AUTOSAR XML (schema 4-2-2)
package /STELLANTIS/EPT/ASWCs
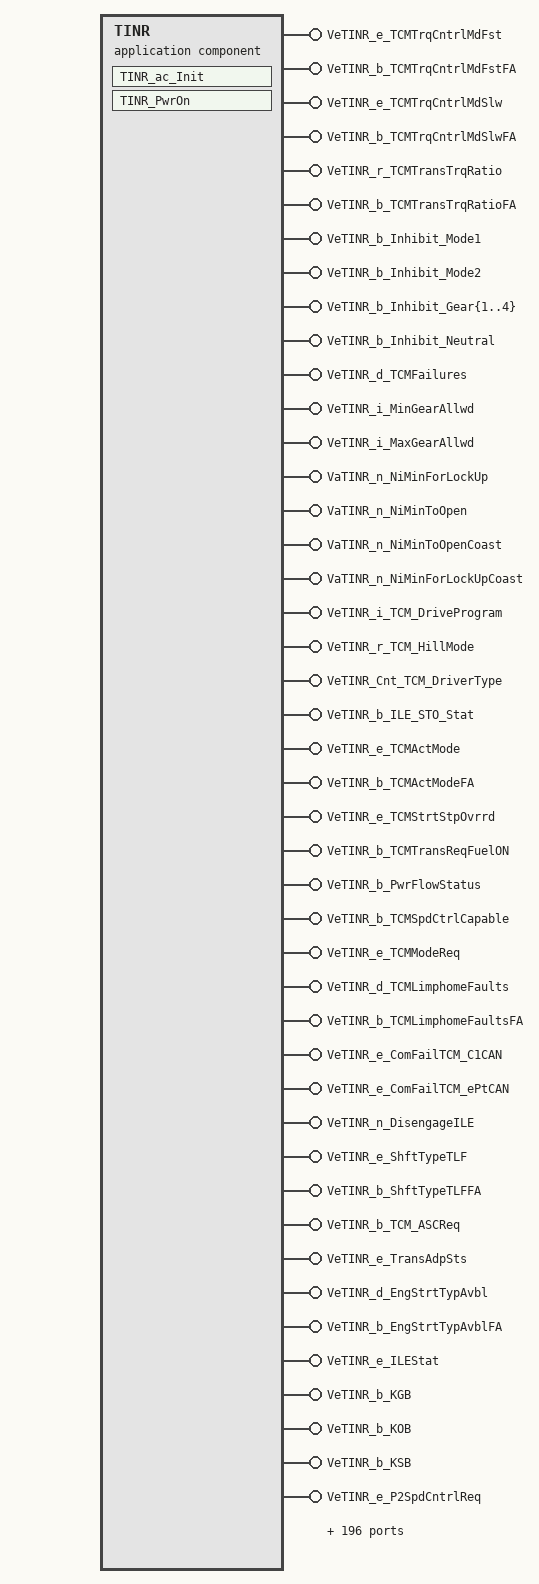
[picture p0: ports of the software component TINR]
  application sw component type TINR
    249 x provide port:
      VeTINR_e_TCMTrqCntrlMdFst: nonqueued-sender-com-spec{data-element=Value, init-value=CeTINR_e_None}, provided-interface=VeTINR_e_TCMTrqCntrlMdFst
      VeTINR_b_TCMTrqCntrlMdFstFA: nonqueued-sender-com-spec{data-element=Value, init-value=0}, provided-interface=VeTINR_b_TCMTrqCntrlMdFstFA
      VeTINR_e_TCMTrqCntrlMdSlw: nonqueued-sender-com-spec{data-element=Value, init-value=CeTINR_e_None}, provided-interface=VeTINR_e_TCMTrqCntrlMdSlw
      VeTINR_b_TCMTrqCntrlMdSlwFA: nonqueued-sender-com-spec{data-element=Value, init-value=0}, provided-interface=VeTINR_b_TCMTrqCntrlMdSlwFA
      VeTINR_r_TCMTransTrqRatio: nonqueued-sender-com-spec{data-element=Value, init-value=0}, provided-interface=VeTINR_r_TCMTransTrqRatio
      VeTINR_b_TCMTransTrqRatioFA: nonqueued-sender-com-spec{data-element=Value, init-value=0}, provided-interface=VeTINR_b_TCMTransTrqRatioFA
      VeTINR_b_Inhibit_Mode1: nonqueued-sender-com-spec{data-element=Value, init-value=0}, provided-interface=VeTINR_b_Inhibit_Mode1
      VeTINR_b_Inhibit_Mode2: nonqueued-sender-com-spec{data-element=Value, init-value=0}, provided-interface=VeTINR_b_Inhibit_Mode2
      VeTINR_b_Inhibit_Gear{1..4}: nonqueued-sender-com-spec{data-element=Value, init-value=0}, provided-interface=VeTINR_b_Inhibit_Gear{1..4}
      VeTINR_b_Inhibit_Neutral: nonqueued-sender-com-spec{data-element=Value, init-value=0}, provided-interface=VeTINR_b_Inhibit_Neutral
      VeTINR_d_TCMFailures: nonqueued-sender-com-spec{data-element=Value, init-value=0}, provided-interface=VeTINR_d_TCMFailures
      VeTINR_i_MinGearAllwd: nonqueued-sender-com-spec{data-element=Value, init-value=0}, provided-interface=VeTINR_i_MinGearAllwd
      VeTINR_i_MaxGearAllwd: nonqueued-sender-com-spec{data-element=Value, init-value=0}, provided-interface=VeTINR_i_MaxGearAllwd
      VaTINR_n_NiMinForLockUp: nonqueued-sender-com-spec{data-element=Value, init-value=9 x 0}, provided-interface=VaTINR_n_NiMinForLockUp
      VaTINR_n_NiMinToOpen: nonqueued-sender-com-spec{data-element=Value, init-value=9 x 0}, provided-interface=VaTINR_n_NiMinToOpen
      VaTINR_n_NiMinToOpenCoast: nonqueued-sender-com-spec{data-element=Value, init-value=9 x 0}, provided-interface=VaTINR_n_NiMinToOpenCoast
      VaTINR_n_NiMinForLockUpCoast: nonqueued-sender-com-spec{data-element=Value, init-value=9 x 0}, provided-interface=VaTINR_n_NiMinForLockUpCoast
      VeTINR_i_TCM_DriveProgram: nonqueued-sender-com-spec{data-element=Value, init-value=0}, provided-interface=VeTINR_i_TCM_DriveProgram
      VeTINR_r_TCM_HillMode: nonqueued-sender-com-spec{data-element=Value, init-value=0}, provided-interface=VeTINR_r_TCM_HillMode
      VeTINR_Cnt_TCM_DriverType: nonqueued-sender-com-spec{data-element=Value, init-value=0}, provided-interface=VeTINR_Cnt_TCM_DriverType
      VeTINR_b_ILE_STO_Stat: nonqueued-sender-com-spec{data-element=Value, init-value=0}, provided-interface=VeTINR_b_ILE_STO_Stat
      VeTINR_e_TCMActMode: nonqueued-sender-com-spec{data-element=Value, init-value=CeTRNR_e_SerEngOff}, provided-interface=VeTINR_e_TCMActMode
      VeTINR_b_TCMActModeFA: nonqueued-sender-com-spec{data-element=Value, init-value=0}, provided-interface=VeTINR_b_TCMActModeFA
      VeTINR_e_TCMStrtStpOvrrd: nonqueued-sender-com-spec{data-element=Value, init-value=CeSTRR_e_NoOvrrd}, provided-interface=VeTINR_e_TCMStrtStpOvrrd
      VeTINR_b_TCMTransReqFuelON: nonqueued-sender-com-spec{data-element=Value, init-value=0}, provided-interface=VeTINR_b_TCMTransReqFuelON
      VeTINR_b_PwrFlowStatus: nonqueued-sender-com-spec{data-element=Value, init-value=0}, provided-interface=VeTINR_b_PwrFlowStatus
      VeTINR_b_TCMSpdCtrlCapable: nonqueued-sender-com-spec{data-element=Value, init-value=0}, provided-interface=VeTINR_b_TCMSpdCtrlCapable
      VeTINR_e_TCMModeReq: nonqueued-sender-com-spec{data-element=Value, init-value=CeOHSR_e_RngSel_N}, provided-interface=VeTINR_e_TCMModeReq
      VeTINR_d_TCMLimphomeFaults: nonqueued-sender-com-spec{data-element=Value, init-value=0}, provided-interface=VeTINR_d_TCMLimphomeFaults
      VeTINR_b_TCMLimphomeFaultsFA: nonqueued-sender-com-spec{data-element=Value, init-value=0}, provided-interface=VeTINR_b_TCMLimphomeFaultsFA
      VeTINR_e_ComFailTCM_C1CAN: nonqueued-sender-com-spec{data-element=Value, init-value=CeTINR_e_NoFaultTCM_C1}, provided-interface=VeTINR_e_ComFailTCM_C1CAN
      VeTINR_e_ComFailTCM_ePtCAN: nonqueued-sender-com-spec{data-element=Value, init-value=CeTINR_e_NoFaultTCM_ePT}, provided-interface=VeTINR_e_ComFailTCM_ePtCAN
      VeTINR_n_DisengageILE: nonqueued-sender-com-spec{data-element=Value, init-value=0}, provided-interface=VeTINR_n_DisengageILE
      VeTINR_e_ShftTypeTLF: nonqueued-sender-com-spec{data-element=Value, init-value=CeTRNR_e_SteadyStateDCT}, provided-interface=VeTINR_e_ShftTypeTLF
      VeTINR_b_ShftTypeTLFFA: nonqueued-sender-com-spec{data-element=Value, init-value=0}, provided-interface=VeTINR_b_ShftTypeTLFFA
      VeTINR_b_TCM_ASCReq: nonqueued-sender-com-spec{data-element=Value, init-value=0}, provided-interface=VeTINR_b_TCM_ASCReq
      VeTINR_e_TransAdpSts: nonqueued-sender-com-spec{data-element=Value, init-value=CeTINR_e_No_Routine_Running}, provided-interface=VeTINR_e_TransAdpSts
      VeTINR_d_EngStrtTypAvbl: nonqueued-sender-com-spec{data-element=Value, init-value=0}, provided-interface=VeTINR_d_EngStrtTypAvbl
      VeTINR_b_EngStrtTypAvblFA: nonqueued-sender-com-spec{data-element=Value, init-value=0}, provided-interface=VeTINR_b_EngStrtTypAvblFA
      VeTINR_e_ILEStat: nonqueued-sender-com-spec{data-element=Value, init-value=CeOHSR_e_NeutralState}, provided-interface=VeTINR_e_ILEStat
      VeTINR_b_KGB: nonqueued-sender-com-spec{data-element=Value, init-value=0}, provided-interface=VeTINR_b_KGB
      VeTINR_b_KOB: nonqueued-sender-com-spec{data-element=Value, init-value=0}, provided-interface=VeTINR_b_KOB
      VeTINR_b_KSB: nonqueued-sender-com-spec{data-element=Value, init-value=0}, provided-interface=VeTINR_b_KSB
      VeTINR_e_P2SpdCntrlReq: nonqueued-sender-com-spec{data-element=Value, init-value=CeTINR_e_Inactive}, provided-interface=VeTINR_e_P2SpdCntrlReq
      VeTINR_e_K1Status: nonqueued-sender-com-spec{data-element=Value, init-value=CeHCCR_e_ClInvalid}, provided-interface=VeTINR_e_K1Status
      VeTINR_e_HASStatusK0: nonqueued-sender-com-spec{data-element=Value, init-value=CeHCCR_e_ClInvalid}, provided-interface=VeTINR_e_HASStatusK0
      VeTINR_e_Synchro2Sts: nonqueued-sender-com-spec{data-element=Value, init-value=CeHCCR_e_ClInvalid}, provided-interface=VeTINR_e_Synchro2Sts
      VeTINR_e_ActualGear: nonqueued-sender-com-spec{data-element=Value, init-value=CeTRNR_e_Neutral}, provided-interface=VeTINR_e_ActualGear
      VeTINR_b_ActualGearFA: nonqueued-sender-com-spec{data-element=Value, init-value=0}, provided-interface=VeTINR_b_ActualGearFA
      VeTINR_e_ShftType: nonqueued-sender-com-spec{data-element=Value, init-value=CeTRNR_e_SteadyState}, provided-interface=VeTINR_e_ShftType
      VeTINR_b_ShftTypeFA: nonqueued-sender-com-spec{data-element=Value, init-value=0}, provided-interface=VeTINR_b_ShftTypeFA
      VeTINR_e_TCM_ActiveEVGear: nonqueued-sender-com-spec{data-element=Value, init-value=CeTRNR_e_Neutral}, provided-interface=VeTINR_e_TCM_ActiveEVGear
      VeTINR_b_TCM_ActiveEVGearFA: nonqueued-sender-com-spec{data-element=Value, init-value=0}, provided-interface=VeTINR_b_TCM_ActiveEVGearFA
      VeTINR_e_TCM_ActiveXNGear: nonqueued-sender-com-spec{data-element=Value, init-value=CeTRNR_e_Neutral}, provided-interface=VeTINR_e_TCM_ActiveXNGear
      VeTINR_b_TCM_ActiveXNGearFA: nonqueued-sender-com-spec{data-element=Value, init-value=0}, provided-interface=VeTINR_b_TCM_ActiveXNGearFA
      VeTINR_e_TCM_ActiveHybridGear: nonqueued-sender-com-spec{data-element=Value, init-value=CeTRNR_e_Neutral}, provided-interface=VeTINR_e_TCM_ActiveHybridGear
      VeTINR_b_TCM_ActiveHybridGearFA: nonqueued-sender-com-spec{data-element=Value, init-value=0}, provided-interface=VeTINR_b_TCM_ActiveHybridGearFA
      VeTINR_e_TCM_PassiveHybridGear: nonqueued-sender-com-spec{data-element=Value, init-value=CeTRNR_e_Neutral}, provided-interface=VeTINR_e_TCM_PassiveHybridGear
      VeTINR_b_TCM_PassiveHybridGearFA: nonqueued-sender-com-spec{data-element=Value, init-value=0}, provided-interface=VeTINR_b_TCM_PassiveHybridGearFA
      VeTINR_e_TargetGear: nonqueued-sender-com-spec{data-element=Value, init-value=CeTRNR_e_Neutral}, provided-interface=VeTINR_e_TargetGear
      VeTINR_b_TargetGearFA: nonqueued-sender-com-spec{data-element=Value, init-value=0}, provided-interface=VeTINR_b_TargetGearFA
      VeTINR_e_TCM_ClutchStartGear: nonqueued-sender-com-spec{data-element=Value, init-value=CeTRNR_e_Neutral}, provided-interface=VeTINR_e_TCM_ClutchStartGear
      VeTINR_e_TransLimpRequest: nonqueued-sender-com-spec{data-element=Value, init-value=CeTINR_e_LimpInactive}, provided-interface=VeTINR_e_TransLimpRequest
      VeTINR_e_Synchro1Gear: nonqueued-sender-com-spec{data-element=Value, init-value=CeTRNR_e_Neutral}, provided-interface=VeTINR_e_Synchro1Gear
      VeTINR_b_Synchro1GearFA: nonqueued-sender-com-spec{data-element=Value, init-value=0}, provided-interface=VeTINR_b_Synchro1GearFA
      VeTINR_e_Synchro2Gear: nonqueued-sender-com-spec{data-element=Value, init-value=CeTRNR_e_Neutral}, provided-interface=VeTINR_e_Synchro2Gear
      VeTINR_b_Synchro2GearFA: nonqueued-sender-com-spec{data-element=Value, init-value=0}, provided-interface=VeTINR_b_Synchro2GearFA
      VeTINR_Pct_TransStrssFctr: nonqueued-sender-com-spec{data-element=Value, init-value=0}, provided-interface=VeTINR_Pct_TransStrssFctr
      VeTINR_e_Synchro1Sts: nonqueued-sender-com-spec{data-element=Value, init-value=CeHCCR_e_ClInvalid}, provided-interface=VeTINR_e_Synchro1Sts
      VeTINR_e_TCMTCCPreventionID: nonqueued-sender-com-spec{data-element=Value, init-value=CeTINR_e_TCCPreventIdInit}, provided-interface=VeTINR_e_TCMTCCPreventionID
      VaTINR_M_ClchTrq: nonqueued-sender-com-spec{data-element=Value, init-value=6 x 0}, provided-interface=VaTINR_M_ClchTrq
      VeTINR_b_ClchTrqFA: nonqueued-sender-com-spec{data-element=Value, init-value=0}, provided-interface=VeTINR_b_ClchTrqFA
      VeTINR_M_ActualClch1_TCM: nonqueued-sender-com-spec{data-element=Value, init-value=0}, provided-interface=VeTINR_M_ActualClch1_TCM
      VeTINR_M_ActualClch3_TCM: nonqueued-sender-com-spec{data-element=Value, init-value=0}, provided-interface=VeTINR_M_ActualClch3_TCM
      VeTINR_e_Clch1Sts: nonqueued-sender-com-spec{data-element=Value, init-value=CeTMMR_e_ClchReleased}, provided-interface=VeTINR_e_Clch1Sts
      VeTINR_e_Clch3Sts: nonqueued-sender-com-spec{data-element=Value, init-value=CeTMMR_e_ClchReleased}, provided-interface=VeTINR_e_Clch3Sts
      VeTINR_e_MtrBDynFctr: nonqueued-sender-com-spec{data-element=Value, init-value=CeTMMR_e_MtrBDynFctr_Inactive}, provided-interface=VeTINR_e_MtrBDynFctr
      VeTINR_b_ClchFaultActv: nonqueued-sender-com-spec{data-element=Value, init-value=0}, provided-interface=VeTINR_b_ClchFaultActv
      VeTINR_b_DsblAEMD4TCM: nonqueued-sender-com-spec{data-element=Value, init-value=0}, provided-interface=VeTINR_b_DsblAEMD4TCM
      VeTINR_t_TCM_TimeToSpeedChange: nonqueued-sender-com-spec{data-element=Value, init-value=0}, provided-interface=VeTINR_t_TCM_TimeToSpeedChange
      VeTINR_M_DrvLnTrqRq_Axle: nonqueued-sender-com-spec{data-element=Value, init-value=0}, provided-interface=VeTINR_M_DrvLnTrqRq_Axle
      VeTINR_b_DrvLnTrqRq_Axle_FA: nonqueued-sender-com-spec{data-element=Value, init-value=0}, provided-interface=VeTINR_b_DrvLnTrqRq_Axle_FA
      VeTINR_b_DrvLnMinTrqMd: nonqueued-sender-com-spec{data-element=Value, init-value=0}, provided-interface=VeTINR_b_DrvLnMinTrqMd
      VeTINR_b_Mech_DrivelineRatioFA: nonqueued-sender-com-spec{data-element=Value, init-value=0}, provided-interface=VeTINR_b_Mech_DrivelineRatioFA
      VeTINR_r_Mech_DrivelineRatio: nonqueued-sender-com-spec{data-element=Value, init-value=0}, provided-interface=VeTINR_r_Mech_DrivelineRatio
      VeTINR_r_TCC_TR_Gen4: nonqueued-sender-com-spec{data-element=Value, init-value=0}, provided-interface=VeTINR_r_TCC_TR_Gen4
      VeTINR_b_TCC_TR_Gen4FA: nonqueued-sender-com-spec{data-element=Value, init-value=0}, provided-interface=VeTINR_b_TCC_TR_Gen4FA
      FsftTINR_Cnt_TCM_DriverType: server-com-spec=FsftTINR_Cnt_TCM_DriverType, provided-interface=FsftTINR_Cnt_TCM_DriverType
      FsftTINR_M_ActualClutch1_TCM: server-com-spec=FsftTINR_M_ActualClutch1_TCM, provided-interface=FsftTINR_M_ActualClutch1_TCM
      FsftTINR_M_ActualClutch3_TCM: server-com-spec=FsftTINR_M_ActualClutch3_TCM, provided-interface=FsftTINR_M_ActualClutch3_TCM
      FsftTINR_M_ClchTrqA: server-com-spec=FsftTINR_M_ClchTrqA, provided-interface=FsftTINR_M_ClchTrqA
      FsftTINR_M_ClchTrqB: server-com-spec=FsftTINR_M_ClchTrqB, provided-interface=FsftTINR_M_ClchTrqB
      FsftTINR_M_ClchTrqC: server-com-spec=FsftTINR_M_ClchTrqC, provided-interface=FsftTINR_M_ClchTrqC
      FsftTINR_M_ClchTrqD: server-com-spec=FsftTINR_M_ClchTrqD, provided-interface=FsftTINR_M_ClchTrqD
      FsftTINR_M_ClchTrqE: server-com-spec=FsftTINR_M_ClchTrqE, provided-interface=FsftTINR_M_ClchTrqE
      FsftTINR_M_ClchTrqF: server-com-spec=FsftTINR_M_ClchTrqF, provided-interface=FsftTINR_M_ClchTrqF
      FsftTINR_M_LeadClutch1_TCM: server-com-spec=FsftTINR_M_LeadClutch1_TCM, provided-interface=FsftTINR_M_LeadClutch1_TCM
      FsftTINR_M_LeadClutch3_TCM: server-com-spec=FsftTINR_M_LeadClutch3_TCM, provided-interface=FsftTINR_M_LeadClutch3_TCM
      FsftTINR_Pct_TransStrssFctr: server-com-spec=FsftTINR_Pct_TransStrssFctr, provided-interface=FsftTINR_Pct_TransStrssFctr
      FsftTINR_b_DrvLnMinTrqMd: server-com-spec=FsftTINR_b_DrvLnMinTrqMd, provided-interface=FsftTINR_b_DrvLnMinTrqMd
      FsftTINR_b_DrvLnTrqRq_Axle: server-com-spec=FsftTINR_b_DrvLnTrqRq_Axle, provided-interface=FsftTINR_b_DrvLnTrqRq_Axle
      FsftTINR_b_DsblAEMD4TCM: server-com-spec=FsftTINR_b_DsblAEMD4TCM, provided-interface=FsftTINR_b_DsblAEMD4TCM
      FsftTINR_b_ILE_STO_Stat: server-com-spec=FsftTINR_b_ILE_STO_Stat, provided-interface=FsftTINR_b_ILE_STO_Stat
      FsftTINR_b_Inhibit_Gear{1..4}: server-com-spec=FsftTINR_b_Inhibit_Gear{1..4}, provided-interface=FsftTINR_b_Inhibit_Gear{1..4}
      FsftTINR_b_Inhibit_Mode1: server-com-spec=FsftTINR_b_Inhibit_Mode1, provided-interface=FsftTINR_b_Inhibit_Mode1
      FsftTINR_b_Inhibit_Mode2: server-com-spec=FsftTINR_b_Inhibit_Mode2, provided-interface=FsftTINR_b_Inhibit_Mode2
      FsftTINR_b_Inhibit_Neutral: server-com-spec=FsftTINR_b_Inhibit_Neutral, provided-interface=FsftTINR_b_Inhibit_Neutral
      FsftTINR_b_KGB: server-com-spec=FsftTINR_b_KGB, provided-interface=FsftTINR_b_KGB
      FsftTINR_b_KOB: server-com-spec=FsftTINR_b_KOB, provided-interface=FsftTINR_b_KOB
      FsftTINR_b_KSB: server-com-spec=FsftTINR_b_KSB, provided-interface=FsftTINR_b_KSB
      FsftTINR_b_PwrFlowStatus: server-com-spec=FsftTINR_b_PwrFlowStatus, provided-interface=FsftTINR_b_PwrFlowStatus
      FsftTINR_b_TCMSpdCtrlCapable: server-com-spec=FsftTINR_b_TCMSpdCtrlCapable, provided-interface=FsftTINR_b_TCMSpdCtrlCapable
      FsftTINR_b_TCMTransReqFuelON: server-com-spec=FsftTINR_b_TCMTransReqFuelON, provided-interface=FsftTINR_b_TCMTransReqFuelON
      FsftTINR_b_TCM_ASCReq: server-com-spec=FsftTINR_b_TCM_ASCReq, provided-interface=FsftTINR_b_TCM_ASCReq
      FsftTINR_d_EngStrtTypAvbl: server-com-spec=FsftTINR_d_EngStrtTypAvbl, provided-interface=FsftTINR_d_EngStrtTypAvbl
      FsftTINR_d_TCMFailures: server-com-spec=FsftTINR_d_TCMFailures, provided-interface=FsftTINR_d_TCMFailures
      FsftTINR_d_TCMLimphomeFaults: server-com-spec=FsftTINR_d_TCMLimphomeFaults, provided-interface=FsftTINR_d_TCMLimphomeFaults
      FsftTINR_d_TCMLimphomeFaultsC1CAN: server-com-spec=FsftTINR_d_TCMLimphomeFaultsC1CAN, provided-interface=FsftTINR_d_TCMLimphomeFaultsC1CAN
      FsftTINR_e_ActualGear: server-com-spec=FsftTINR_e_ActualGear, provided-interface=FsftTINR_e_ActualGear
      FsftTINR_e_Clch1Sts: server-com-spec=FsftTINR_e_Clch1Sts, provided-interface=FsftTINR_e_Clch1Sts
      FsftTINR_e_Clch3Sts: server-com-spec=FsftTINR_e_Clch3Sts, provided-interface=FsftTINR_e_Clch3Sts
      FsftTINR_e_ComFailDflt_C1CAN: server-com-spec=FsftTINR_e_ComFailDflt_C1CAN, provided-interface=FsftTINR_e_ComFailDflt_C1CAN
      FsftTINR_e_ComFailDflt_ePTCAN: server-com-spec=FsftTINR_e_ComFailDflt_ePTCAN, provided-interface=FsftTINR_e_ComFailDflt_ePTCAN
      FsftTINR_e_GearShftType: server-com-spec=FsftTINR_e_GearShftType, provided-interface=FsftTINR_e_GearShftType
      FsftTINR_e_GearShftType2: server-com-spec=FsftTINR_e_GearShftType2, provided-interface=FsftTINR_e_GearShftType2
      FsftTINR_e_HASStatusK0: server-com-spec=FsftTINR_e_HASStatusK0, provided-interface=FsftTINR_e_HASStatusK0
      FsftTINR_e_ILEStat: server-com-spec=FsftTINR_e_ILEStat, provided-interface=FsftTINR_e_ILEStat
      FsftTINR_e_K1Status: server-com-spec=FsftTINR_e_K1Status, provided-interface=FsftTINR_e_K1Status
      FsftTINR_e_MtrBDynFctr: server-com-spec=FsftTINR_e_MtrBDynFctr, provided-interface=FsftTINR_e_MtrBDynFctr
      FsftTINR_e_P2SpdCntrlReq: server-com-spec=FsftTINR_e_P2SpdCntrlReq, provided-interface=FsftTINR_e_P2SpdCntrlReq
      FsftTINR_e_Synchro1Gear: server-com-spec=FsftTINR_e_Synchro1Gear, provided-interface=FsftTINR_e_Synchro1Gear
      FsftTINR_e_Synchro1Sts: server-com-spec=FsftTINR_e_Synchro1Sts, provided-interface=FsftTINR_e_Synchro1Sts
      FsftTINR_e_Synchro2Gear: server-com-spec=FsftTINR_e_Synchro2Gear, provided-interface=FsftTINR_e_Synchro2Gear
      FsftTINR_e_Synchro2Sts: server-com-spec=FsftTINR_e_Synchro2Sts, provided-interface=FsftTINR_e_Synchro2Sts
      FsftTINR_e_TCMHASActMode: server-com-spec=FsftTINR_e_TCMHASActMode, provided-interface=FsftTINR_e_TCMHASActMode
      FsftTINR_e_TCMModeReq: server-com-spec=FsftTINR_e_TCMModeReq, provided-interface=FsftTINR_e_TCMModeReq
      FsftTINR_e_TCMNeutPhsZeroTrqReq_CANC: server-com-spec=FsftTINR_e_TCMNeutPhsZeroTrqReq_CANC, provided-interface=FsftTINR_e_TCMNeutPhsZeroTrqReq_CANC
      FsftTINR_e_TCMNeutPhsZeroTrqReq_ePTCAN: server-com-spec=FsftTINR_e_TCMNeutPhsZeroTrqReq_ePTCAN, provided-interface=FsftTINR_e_TCMNeutPhsZeroTrqReq_ePTCAN
      FsftTINR_e_TCMStrtStpOvrrd: server-com-spec=FsftTINR_e_TCMStrtStpOvrrd, provided-interface=FsftTINR_e_TCMStrtStpOvrrd
      FsftTINR_e_TCMTCCPreventionID: server-com-spec=FsftTINR_e_TCMTCCPreventionID, provided-interface=FsftTINR_e_TCMTCCPreventionID
      FsftTINR_e_TCMTrqCntrlModeFast: server-com-spec=FsftTINR_e_TCMTrqCntrlModeFast, provided-interface=FsftTINR_e_TCMTrqCntrlModeFast
      FsftTINR_e_TCMTrqCntrlModeSlow: server-com-spec=FsftTINR_e_TCMTrqCntrlModeSlow, provided-interface=FsftTINR_e_TCMTrqCntrlModeSlow
      FsftTINR_e_TCM_ActiveEVGear: server-com-spec=FsftTINR_e_TCM_ActiveEVGear, provided-interface=FsftTINR_e_TCM_ActiveEVGear
      FsftTINR_e_TCM_ActiveHybridGear: server-com-spec=FsftTINR_e_TCM_ActiveHybridGear, provided-interface=FsftTINR_e_TCM_ActiveHybridGear
      FsftTINR_e_TCM_ActiveXNGear: server-com-spec=FsftTINR_e_TCM_ActiveXNGear, provided-interface=FsftTINR_e_TCM_ActiveXNGear
      FsftTINR_e_TCM_ClutchStartGear: server-com-spec=FsftTINR_e_TCM_ClutchStartGear, provided-interface=FsftTINR_e_TCM_ClutchStartGear
      FsftTINR_e_TCM_PassiveHybridGear: server-com-spec=FsftTINR_e_TCM_PassiveHybridGear, provided-interface=FsftTINR_e_TCM_PassiveHybridGear
      FsftTINR_e_TargetGear: server-com-spec=FsftTINR_e_TargetGear, provided-interface=FsftTINR_e_TargetGear
      FsftTINR_e_TransAdpStatus: server-com-spec=FsftTINR_e_TransAdpStatus, provided-interface=FsftTINR_e_TransAdpStatus
      FsftTINR_i_TCM_DriveProgram: server-com-spec=FsftTINR_i_TCM_DriveProgram, provided-interface=FsftTINR_i_TCM_DriveProgram
      FsftTINR_i_TCM_MaxGearAllwd: server-com-spec=FsftTINR_i_TCM_MaxGearAllwd, provided-interface=FsftTINR_i_TCM_MaxGearAllwd
      FsftTINR_i_TCM_MinGearAllwd: server-com-spec=FsftTINR_i_TCM_MinGearAllwd, provided-interface=FsftTINR_i_TCM_MinGearAllwd
      FsftTINR_n_DisengageILE: server-com-spec=FsftTINR_n_DisengageILE, provided-interface=FsftTINR_n_DisengageILE
      FsftTINR_n_NiMinForLockUp: server-com-spec=FsftTINR_n_NiMinForLockUp, provided-interface=FsftTINR_n_NiMinForLockUp
      FsftTINR_n_NiMinForLockUpCoast: server-com-spec=FsftTINR_n_NiMinForLockUpCoast, provided-interface=FsftTINR_n_NiMinForLockUpCoast
      FsftTINR_n_NiMinToOpen: server-com-spec=FsftTINR_n_NiMinToOpen, provided-interface=FsftTINR_n_NiMinToOpen
      FsftTINR_n_NiMinToOpenCoast: server-com-spec=FsftTINR_n_NiMinToOpenCoast, provided-interface=FsftTINR_n_NiMinToOpenCoast
      FsftTINR_r_DriveLineRatioCanC: server-com-spec=FsftTINR_r_DriveLineRatioCanC, provided-interface=FsftTINR_r_DriveLineRatioCanC
      FsftTINR_r_DriveLineRatioEpt: server-com-spec=FsftTINR_r_DriveLineRatioEpt, provided-interface=FsftTINR_r_DriveLineRatioEpt
      FsftTINR_r_MechDrivelineRatio: server-com-spec=FsftTINR_r_MechDrivelineRatio, provided-interface=FsftTINR_r_MechDrivelineRatio
      FsftTINR_r_TCC_TR: server-com-spec=FsftTINR_r_TCC_TR, provided-interface=FsftTINR_r_TCC_TR
      FsftTINR_r_TCM_HillMode: server-com-spec=FsftTINR_r_TCM_HillMode, provided-interface=FsftTINR_r_TCM_HillMode
      FsftTINR_r_TransTrqRatio: server-com-spec=FsftTINR_r_TransTrqRatio, provided-interface=FsftTINR_r_TransTrqRatio
      PokeTINR_Cnt_TCM_DriverType: server-com-spec{operation=PokeTINR_Cnt_TCM_DriverType, queue-length=1}, provided-interface=PokeTINR_Cnt_TCM_DriverType
      PokeTINR_M_ActualClutch1_TCM: server-com-spec{operation=PokeTINR_M_ActualClutch1_TCM, queue-length=1}, provided-interface=PokeTINR_M_ActualClutch1_TCM
      PokeTINR_M_ActualClutch3_TCM: server-com-spec{operation=PokeTINR_M_ActualClutch3_TCM, queue-length=1}, provided-interface=PokeTINR_M_ActualClutch3_TCM
      PokeTINR_M_ClchTrqA: server-com-spec{operation=PokeTINR_M_ClchTrqA, queue-length=1}, provided-interface=PokeTINR_M_ClchTrqA
      PokeTINR_M_ClchTrqB: server-com-spec{operation=PokeTINR_M_ClchTrqB, queue-length=1}, provided-interface=PokeTINR_M_ClchTrqB
      PokeTINR_M_ClchTrqC: server-com-spec{operation=PokeTINR_M_ClchTrqC, queue-length=1}, provided-interface=PokeTINR_M_ClchTrqC
      PokeTINR_M_ClchTrqD: server-com-spec{operation=PokeTINR_M_ClchTrqD, queue-length=1}, provided-interface=PokeTINR_M_ClchTrqD
      PokeTINR_M_ClchTrqE: server-com-spec{operation=PokeTINR_M_ClchTrqE, queue-length=1}, provided-interface=PokeTINR_M_ClchTrqE
      PokeTINR_M_ClchTrqF: server-com-spec{operation=PokeTINR_M_ClchTrqF, queue-length=1}, provided-interface=PokeTINR_M_ClchTrqF
      PokeTINR_M_DrvLnTrqRq_Axle: server-com-spec{operation=PokeTINR_M_DrvLnTrqRq_Axle, queue-length=1}, provided-interface=PokeTINR_M_DrvLnTrqRq_Axle
      PokeTINR_M_LeadClutch1_TCM: server-com-spec{operation=PokeTINR_M_LeadClutch1_TCM, queue-length=1}, provided-interface=PokeTINR_M_LeadClutch1_TCM
      PokeTINR_M_LeadClutch3_TCM: server-com-spec{operation=PokeTINR_M_LeadClutch3_TCM, queue-length=1}, provided-interface=PokeTINR_M_LeadClutch3_TCM
      PokeTINR_Pct_TransStrssFctr: server-com-spec{operation=PokeTINR_Pct_TransStrssFctr, queue-length=1}, provided-interface=PokeTINR_Pct_TransStrssFctr
      PokeTINR_b_DrvLnMinTrqMd: server-com-spec{operation=PokeTINR_b_DrvLnMinTrqMd, queue-length=1}, provided-interface=PokeTINR_b_DrvLnMinTrqMd
      PokeTINR_b_DsblAEMD4TCM: server-com-spec{operation=PokeTINR_b_DsblAEMD4TCM, queue-length=1}, provided-interface=PokeTINR_b_DsblAEMD4TCM
      PokeTINR_b_ILE_STO_Stat: server-com-spec{operation=PokeTINR_b_ILE_STO_Stat, queue-length=1}, provided-interface=PokeTINR_b_ILE_STO_Stat
      PokeTINR_b_Inhibit_Gear{1..4}: server-com-spec{operation=PokeTINR_b_Inhibit_Gear{1..4}, queue-length=1}, provided-interface=PokeTINR_b_Inhibit_Gear{1..4}
      PokeTINR_b_Inhibit_Mode1: server-com-spec{operation=PokeTINR_b_Inhibit_Mode1, queue-length=1}, provided-interface=PokeTINR_b_Inhibit_Mode1
      PokeTINR_b_Inhibit_Mode2: server-com-spec{operation=PokeTINR_b_Inhibit_Mode2, queue-length=1}, provided-interface=PokeTINR_b_Inhibit_Mode2
      PokeTINR_b_Inhibit_Neutral: server-com-spec{operation=PokeTINR_b_Inhibit_Neutral, queue-length=1}, provided-interface=PokeTINR_b_Inhibit_Neutral
      PokeTINR_b_KGB: server-com-spec{operation=PokeTINR_b_KGB, queue-length=1}, provided-interface=PokeTINR_b_KGB
      PokeTINR_b_KOB: server-com-spec{operation=PokeTINR_b_KOB, queue-length=1}, provided-interface=PokeTINR_b_KOB
      PokeTINR_b_KSB: server-com-spec{operation=PokeTINR_b_KSB, queue-length=1}, provided-interface=PokeTINR_b_KSB
      PokeTINR_b_PwrFlowStatus: server-com-spec{operation=PokeTINR_b_PwrFlowStatus, queue-length=1}, provided-interface=PokeTINR_b_PwrFlowStatus
      PokeTINR_b_TCMSpdCtrlCapable: server-com-spec{operation=PokeTINR_b_TCMSpdCtrlCapable, queue-length=1}, provided-interface=PokeTINR_b_TCMSpdCtrlCapable
      PokeTINR_b_TCMTransReqFuelON: server-com-spec{operation=PokeTINR_b_TCMTransReqFuelON, queue-length=1}, provided-interface=PokeTINR_b_TCMTransReqFuelON
      PokeTINR_b_TCM_ASCReq: server-com-spec{operation=PokeTINR_b_TCM_ASCReq, queue-length=1}, provided-interface=PokeTINR_b_TCM_ASCReq
      PokeTINR_d_EngStrtTypAvbl: server-com-spec{operation=PokeTINR_d_EngStrtTypAvbl, queue-length=1}, provided-interface=PokeTINR_d_EngStrtTypAvbl
      PokeTINR_d_TCMFailures: server-com-spec{operation=PokeTINR_d_TCMFailures, queue-length=1}, provided-interface=PokeTINR_d_TCMFailures
      PokeTINR_d_TCMLimphomeFaults: server-com-spec{operation=PokeTINR_d_TCMLimphomeFaults, queue-length=1}, provided-interface=PokeTINR_d_TCMLimphomeFaults
      PokeTINR_d_TCMLimphomeFaultsC1CAN: server-com-spec{operation=PokeTINR_d_TCMLimphomeFaultsC1CAN, queue-length=1}, provided-interface=PokeTINR_d_TCMLimphomeFaultsC1CAN
      PokeTINR_e_ActualGear: server-com-spec{operation=PokeTINR_e_ActualGear, queue-length=1}, provided-interface=PokeTINR_e_ActualGear
      PokeTINR_e_Clch1Sts: server-com-spec{operation=PokeTINR_e_Clch1Sts, queue-length=1}, provided-interface=PokeTINR_e_Clch1Sts
      PokeTINR_e_Clch3Sts: server-com-spec{operation=PokeTINR_e_Clch3Sts, queue-length=1}, provided-interface=PokeTINR_e_Clch3Sts
      PokeTINR_e_ComFail_C1CAN: server-com-spec{operation=PokeTINR_e_ComFail_C1CAN, queue-length=1}, provided-interface=PokeTINR_e_ComFail_C1CAN
      PokeTINR_e_ComFail_ePTCAN: server-com-spec{operation=PokeTINR_e_ComFail_ePTCAN, queue-length=1}, provided-interface=PokeTINR_e_ComFail_ePTCAN
      PokeTINR_e_GearShftType: server-com-spec{operation=PokeTINR_e_GearShftType, queue-length=1}, provided-interface=PokeTINR_e_GearShftType
      PokeTINR_e_GearShftType2: server-com-spec{operation=PokeTINR_e_GearShftType2, queue-length=1}, provided-interface=PokeTINR_e_GearShftType2
      PokeTINR_e_HASStatusK0: server-com-spec{operation=PokeTINR_e_HASStatusK0, queue-length=1}, provided-interface=PokeTINR_e_HASStatusK0
      PokeTINR_e_ILEStat: server-com-spec{operation=PokeTINR_e_ILEStat, queue-length=1}, provided-interface=PokeTINR_e_ILEStat
      PokeTINR_e_K1Status: server-com-spec{operation=PokeTINR_e_K1Status, queue-length=1}, provided-interface=PokeTINR_e_K1Status
      PokeTINR_e_MtrBDynFctr: server-com-spec{operation=PokeTINR_e_MtrBDynFctr, queue-length=1}, provided-interface=PokeTINR_e_MtrBDynFctr
      PokeTINR_e_P2SpdCntrlReq: server-com-spec{operation=PokeTINR_e_P2SpdCntrlReq, queue-length=1}, provided-interface=PokeTINR_e_P2SpdCntrlReq
      PokeTINR_e_Synchro1Gear: server-com-spec{operation=PokeTINR_e_Synchro1Gear, queue-length=1}, provided-interface=PokeTINR_e_Synchro1Gear
      PokeTINR_e_Synchro1Sts: server-com-spec{operation=PokeTINR_e_Synchro1Sts, queue-length=1}, provided-interface=PokeTINR_e_Synchro1Sts
      PokeTINR_e_Synchro2Gear: server-com-spec{operation=PokeTINR_e_Synchro2Gear, queue-length=1}, provided-interface=PokeTINR_e_Synchro2Gear
      PokeTINR_e_Synchro2Sts: server-com-spec{operation=PokeTINR_e_Synchro2Sts, queue-length=1}, provided-interface=PokeTINR_e_Synchro2Sts
      PokeTINR_e_TCMHASActMode: server-com-spec{operation=PokeTINR_e_TCMHASActMode, queue-length=1}, provided-interface=PokeTINR_e_TCMHASActMode
      PokeTINR_e_TCMModeReq: server-com-spec{operation=PokeTINR_e_TCMModeReq, queue-length=1}, provided-interface=PokeTINR_e_TCMModeReq
      PokeTINR_e_TCMNeutPhsZeroTrqReq_CANC: server-com-spec{operation=PokeTINR_e_TCMNeutPhsZeroTrqReq_CANC, queue-length=1}, provided-interface=PokeTINR_e_TCMNeutPhsZeroTrqReq_CANC
      PokeTINR_e_TCMNeutPhsZeroTrqReq_ePTCAN: server-com-spec{operation=PokeTINR_e_TCMNeutPhsZeroTrqReq_ePTCAN, queue-length=1}, provided-interface=PokeTINR_e_TCMNeutPhsZeroTrqReq_ePTCAN
      PokeTINR_e_TCMStrtStpOvrrd: server-com-spec{operation=PokeTINR_e_TCMStrtStpOvrrd, queue-length=1}, provided-interface=PokeTINR_e_TCMStrtStpOvrrd
      PokeTINR_e_TCMTCCPreventionID: server-com-spec{operation=PokeTINR_e_TCMTCCPreventionID, queue-length=1}, provided-interface=PokeTINR_e_TCMTCCPreventionID
      PokeTINR_e_TCMTrqCntrlModeFast: server-com-spec{operation=PokeTINR_e_TCMTrqCntrlModeFast, queue-length=1}, provided-interface=PokeTINR_e_TCMTrqCntrlModeFast
      PokeTINR_e_TCMTrqCntrlModeSlow: server-com-spec{operation=PokeTINR_e_TCMTrqCntrlModeSlow, queue-length=1}, provided-interface=PokeTINR_e_TCMTrqCntrlModeSlow
      PokeTINR_e_TCM_ActiveEVGear: server-com-spec{operation=PokeTINR_e_TCM_ActiveEVGear, queue-length=1}, provided-interface=PokeTINR_e_TCM_ActiveEVGear
      PokeTINR_e_TCM_ActiveHybridGear: server-com-spec{operation=PokeTINR_e_TCM_ActiveHybridGear, queue-length=1}, provided-interface=PokeTINR_e_TCM_ActiveHybridGear
      PokeTINR_e_TCM_ActiveXNGear: server-com-spec{operation=PokeTINR_e_TCM_ActiveXNGear, queue-length=1}, provided-interface=PokeTINR_e_TCM_ActiveXNGear
      PokeTINR_e_TCM_ClutchStartGear: server-com-spec{operation=PokeTINR_e_TCM_ClutchStartGear, queue-length=1}, provided-interface=PokeTINR_e_TCM_ClutchStartGear
      PokeTINR_e_TCM_PassiveHybridGear: server-com-spec{operation=PokeTINR_e_TCM_PassiveHybridGear, queue-length=1}, provided-interface=PokeTINR_e_TCM_PassiveHybridGear
      PokeTINR_e_TargetGear: server-com-spec{operation=PokeTINR_e_TargetGear, queue-length=1}, provided-interface=PokeTINR_e_TargetGear
      PokeTINR_e_TransAdpStatus: server-com-spec{operation=PokeTINR_e_TransAdpStatus, queue-length=1}, provided-interface=PokeTINR_e_TransAdpStatus
      PokeTINR_i_TCM_DriveProgram: server-com-spec{operation=PokeTINR_i_TCM_DriveProgram, queue-length=1}, provided-interface=PokeTINR_i_TCM_DriveProgram
      PokeTINR_i_TCM_MaxGearAllwd: server-com-spec{operation=PokeTINR_i_TCM_MaxGearAllwd, queue-length=1}, provided-interface=PokeTINR_i_TCM_MaxGearAllwd
      PokeTINR_i_TCM_MinGearAllwd: server-com-spec{operation=PokeTINR_i_TCM_MinGearAllwd, queue-length=1}, provided-interface=PokeTINR_i_TCM_MinGearAllwd
      PokeTINR_n_DisengageILE: server-com-spec{operation=PokeTINR_n_DisengageILE, queue-length=1}, provided-interface=PokeTINR_n_DisengageILE
      PokeTINR_n_NiMinForLockUp: server-com-spec{operation=PokeTINR_n_NiMinForLockUp, queue-length=1}, provided-interface=PokeTINR_n_NiMinForLockUp
      PokeTINR_n_NiMinForLockUpCoast: server-com-spec{operation=PokeTINR_n_NiMinForLockUpCoast, queue-length=1}, provided-interface=PokeTINR_n_NiMinForLockUpCoast
      PokeTINR_n_NiMinToOpen: server-com-spec{operation=PokeTINR_n_NiMinToOpen, queue-length=1}, provided-interface=PokeTINR_n_NiMinToOpen
      PokeTINR_n_NiMinToOpenCoast: server-com-spec{operation=PokeTINR_n_NiMinToOpenCoast, queue-length=1}, provided-interface=PokeTINR_n_NiMinToOpenCoast
      PokeTINR_r_DriveLineRatioCanC: server-com-spec{operation=PokeTINR_r_DriveLineRatioCanC, queue-length=1}, provided-interface=PokeTINR_r_DriveLineRatioCanC
      PokeTINR_r_DriveLineRatioEpt: server-com-spec{operation=PokeTINR_r_DriveLineRatioEpt, queue-length=1}, provided-interface=PokeTINR_r_DriveLineRatioEpt
      PokeTINR_r_MechDrivelineRatio: server-com-spec{operation=PokeTINR_r_MechDrivelineRatio, queue-length=1}, provided-interface=PokeTINR_r_MechDrivelineRatio
      PokeTINR_r_TCC_TR: server-com-spec{operation=PokeTINR_r_TCC_TR, queue-length=1}, provided-interface=PokeTINR_r_TCC_TR
      PokeTINR_r_TCM_HillMode: server-com-spec{operation=PokeTINR_r_TCM_HillMode, queue-length=1}, provided-interface=PokeTINR_r_TCM_HillMode
      PokeTINR_r_TransTrqRatio: server-com-spec{operation=PokeTINR_r_TransTrqRatio, queue-length=1}, provided-interface=PokeTINR_r_TransTrqRatio
      PokeTINR_t_TCM_TimeToSpeedChange: server-com-spec{operation=PokeTINR_t_TCM_TimeToSpeedChange, queue-length=1}, provided-interface=PokeTINR_t_TCM_TimeToSpeedChange
    behavior IB_TINR: data-type-mapping=msADTtoIDTMapping, handle-termination-and-restart=NO-SUPPORT
      init event Event_TINR_ac_Init: start-on-event=TINR_ac_Init
      init event Event_PwrOn: start-on-event=TINR_PwrOn
      explicit-inter-runnable-variables:
        59 x data, all with sw-calibration-access=READ-ONLY:
          VeTINR_d_TCMLimphomeFaults_write_IRV: category=VALUE, type=SInt16, init-value=0
          VeTINR_d_TCMLimphomeFaultsC1CAN_write_IRV: category=VALUE, type=SInt16, init-value=0
          VeTINR_e_TCMNeutPhsZeroTrqReq_CANC_write_IRV: category=VALUE, type=TeTINR_e_TCMNeutPhsZeroTrqReq, init-value=CeTINR_e_LimpInactive
          VeTINR_b_TCMNeutPhsZeroTrqReq_CANCFA_write_IRV: category=VALUE, type=Boolean, init-value=0
          VeTINR_e_TCMNeutPhsZeroTrqReq_ePTCAN_write_IRV: category=VALUE, type=TeTINR_e_TCMNeutPhsZeroTrqReq, init-value=CeTINR_e_LimpInactive
          VeTINR_b_TCMNeutPhsZeroTrqReq_ePTCANFA_write_IRV: category=VALUE, type=Boolean, init-value=0
          VeTINR_d_TCMFailures_write_IRV: category=VALUE, type=UInt16, init-value=0
          VeTINR_t_TCM_TimeToSpeedChange_write_IRV: category=VALUE, type=Float, init-value=0
          VeTINR_b_TCM_MinGearAllwdFA_write_IRV: category=VALUE, type=Boolean, init-value=0
          VeTINR_i_TCM_MinGearAllwd_write_IRV: category=VALUE, type=SInt16, init-value=0
          VeTINR_b_TCM_MaxGearAllwdFA_write_IRV: category=VALUE, type=Boolean, init-value=0
          VeTINR_i_TCM_MaxGearAllwd_write_IRV: category=VALUE, type=SInt16, init-value=0
          VaTINR_n_NiMinForLockUp_write_IRV: category=ARRAY, type=rt_Array_Float_9, init-value=9 x 0
          VeTINR_b_NiMinForLockUpFA_write_IRV: category=VALUE, type=Boolean, init-value=0
          VaTINR_n_NiMinToOpen_write_IRV: category=ARRAY, type=rt_Array_Float_9, init-value=9 x 0
          VeTINR_b_NiMinToOpenFA_write_IRV: category=VALUE, type=Boolean, init-value=0
          VaTINR_n_NiMinForLockUpCoast_write_IRV: category=ARRAY, type=rt_Array_Float_9, init-value=9 x 0
          VeTINR_b_NiMinForLockUpCoastFA_write_IRV: category=VALUE, type=Boolean, init-value=0
          VaTINR_n_NiMinToOpenCoast_write_IRV: category=ARRAY, type=rt_Array_Float_9, init-value=9 x 0
          VeTINR_b_NiMinToOpenCoastFA_write_IRV: category=VALUE, type=Boolean, init-value=0
          VeTINR_b_TCMLimphomeFaultsFA_write_IRV: category=VALUE, type=Boolean, init-value=0
          VeTINR_b_TCMLimphomeFaultsC1CANFA_write_IRV: category=VALUE, type=Boolean, init-value=0
          VeTINR_e_TransAdpStatus_write_IRV: category=VALUE, type=TeTINR_e_TransAdaptStatus, init-value=CeTINR_e_No_Routine_Running
          VeTINR_b_PwrFlowStatus_write_IRV: category=VALUE, type=Boolean, init-value=0
          VeTINR_r_TCM_HillMode_write_IRV: category=VALUE, type=Float, init-value=0
          VeTINR_r_TransTrqRatio_write_IRV: category=VALUE, type=Float, init-value=0
          VeTINR_r_DriveLineRatioEpt_write_IRV: category=VALUE, type=Float, init-value=0
          VeTINR_b_DriveLineRatioEptFA_write_IRV: category=VALUE, type=Boolean, init-value=0
          VeTINR_r_DriveLineRatioCanC_write_IRV: category=VALUE, type=Float, init-value=0
          VeTINR_b_DriveLineRatioCanCFA_write_IRV: category=VALUE, type=Boolean, init-value=0
          VeTINR_b_DrvLnTrqRq_Axle_write_IRV: category=VALUE, type=Float, init-value=0
          VeTINR_b_DrvLnTrqRq_AxleFA_write_IRV: category=VALUE, type=Boolean, init-value=0
          VeTINR_b_DrvLnMinTrqMd_write_IRV: category=VALUE, type=Boolean, init-value=0
          VeTINR_M_ClchTrqA_write_IRV: category=VALUE, type=Float, init-value=0
          VeTINR_M_ClchTrqB_write_IRV: category=VALUE, type=Float, init-value=0
          VeTINR_M_ClchTrqC_write_IRV: category=VALUE, type=Float, init-value=0
          VeTINR_M_ClchTrqD_write_IRV: category=VALUE, type=Float, init-value=0
          VeTINR_M_ClchTrqE_write_IRV: category=VALUE, type=Float, init-value=0
          VeTINR_M_ClchTrqF_write_IRV: category=VALUE, type=Float, init-value=0
          VeTINR_b_ClchTrqAFA_write_IRV: category=VALUE, type=Boolean, init-value=0
          VeTINR_b_ClchTrqBFA_write_IRV: category=VALUE, type=Boolean, init-value=0
          VeTINR_b_ClchTrqCFA_write_IRV: category=VALUE, type=Boolean, init-value=0
          VeTINR_b_ClchTrqDFA_write_IRV: category=VALUE, type=Boolean, init-value=0
          VeTINR_b_ClchTrqEFA_write_IRV: category=VALUE, type=Boolean, init-value=0
          VeTINR_b_ClchTrqFFA_write_IRV: category=VALUE, type=Boolean, init-value=0
          VeTINR_M_ActualClutch1_TCM_write_IRV: category=VALUE, type=Float, init-value=0
          VeTINR_b_ActualClutch1_TCMFA_write_IRV: category=VALUE, type=Boolean, init-value=0
          VeTINR_M_ActualClutch3_TCM_write_IRV: category=VALUE, type=Float, init-value=0
          VeTINR_b_ActualClutch3_TCMFA_write_IRV: category=VALUE, type=Boolean, init-value=0
          VeTINR_M_LeadClutch1_TCM_write_IRV: category=VALUE, type=Float, init-value=0
          VeTINR_b_LeadClutch1_TCMFA_write_IRV: category=VALUE, type=Boolean, init-value=0
          VeTINR_M_LeadClutch3_TCM_write_IRV: category=VALUE, type=Float, init-value=0
          VeTINR_b_LeadClutch3_TCMFA_write_IRV: category=VALUE, type=Boolean, init-value=0
          VeTINR_e_Clch1Sts_write_IRV: category=VALUE, type=TeTMMR_e_ClchStat_DCT, init-value=CeTMMR_e_ClchReleased
          VeTINR_b_Clch1StsFA_write_IRV: category=VALUE, type=Boolean, init-value=0
          VeTINR_e_Clch3Sts_write_IRV: category=VALUE, type=TeTMMR_e_ClchStat_DCT, init-value=CeTMMR_e_ClchReleased
          VeTINR_b_Clch3StsFA_write_IRV: category=VALUE, type=Boolean, init-value=0
          VeTINR_e_MtrBDynFctr_write_IRV: category=VALUE, type=TeTMMR_e_MtrBDynFctr, init-value=CeTMMR_e_MtrBDynFctr_Inactive
          VeTINR_e_TCMTCCPreventionID_write_IRV: category=VALUE, type=TeTINR_e_TCMTCCPreventionID, init-value=CeTINR_e_TCCPreventIdInit
      runnable TINR_ac_Init
        data-send-points:
          35 x access:
            OUT_VeTINR_e_TCMTrqCntrlMdFst_Value: accessed-variable=VeTINR_e_TCMTrqCntrlMdFst.Value
            OUT_VeTINR_e_TCMTrqCntrlMdSlw_Value: accessed-variable=VeTINR_e_TCMTrqCntrlMdSlw.Value
            OUT_VaTINR_n_NiMinForLockUp_Value: accessed-variable=VaTINR_n_NiMinForLockUp.Value
            OUT_VaTINR_n_NiMinToOpen_Value: accessed-variable=VaTINR_n_NiMinToOpen.Value
            OUT_VaTINR_n_NiMinToOpenCoast_Value: accessed-variable=VaTINR_n_NiMinToOpenCoast.Value
            OUT_VaTINR_n_NiMinForLockUpCoast_Value: accessed-variable=VaTINR_n_NiMinForLockUpCoast.Value
            OUT_VeTINR_e_TCMActMode_Value: accessed-variable=VeTINR_e_TCMActMode.Value
            OUT_VeTINR_e_TCMStrtStpOvrrd_Value: accessed-variable=VeTINR_e_TCMStrtStpOvrrd.Value
            OUT_VeTINR_e_TCMModeReq_Value: accessed-variable=VeTINR_e_TCMModeReq.Value
            OUT_VeTINR_e_ComFailTCM_C1CAN_Value: accessed-variable=VeTINR_e_ComFailTCM_C1CAN.Value
            OUT_VeTINR_e_ComFailTCM_ePtCAN_Value: accessed-variable=VeTINR_e_ComFailTCM_ePtCAN.Value
            OUT_VeTINR_e_ShftTypeTLF_Value: accessed-variable=VeTINR_e_ShftTypeTLF.Value
            OUT_VeTINR_e_TransAdpSts_Value: accessed-variable=VeTINR_e_TransAdpSts.Value
            OUT_VeTINR_e_ILEStat_Value: accessed-variable=VeTINR_e_ILEStat.Value
            OUT_VeTINR_e_P2SpdCntrlReq_Value: accessed-variable=VeTINR_e_P2SpdCntrlReq.Value
            OUT_VeTINR_e_K1Status_Value: accessed-variable=VeTINR_e_K1Status.Value
            OUT_VeTINR_e_HASStatusK0_Value: accessed-variable=VeTINR_e_HASStatusK0.Value
            OUT_VeTINR_e_Synchro2Sts_Value: accessed-variable=VeTINR_e_Synchro2Sts.Value
            OUT_VeTINR_e_ActualGear_Value: accessed-variable=VeTINR_e_ActualGear.Value
            OUT_VeTINR_e_ShftType_Value: accessed-variable=VeTINR_e_ShftType.Value
            OUT_VeTINR_e_TCM_ActiveEVGear_Value: accessed-variable=VeTINR_e_TCM_ActiveEVGear.Value
            OUT_VeTINR_e_TCM_ActiveXNGear_Value: accessed-variable=VeTINR_e_TCM_ActiveXNGear.Value
            OUT_VeTINR_e_TCM_ActiveHybridGear_Value: accessed-variable=VeTINR_e_TCM_ActiveHybridGear.Value
            OUT_VeTINR_e_TCM_PassiveHybridGear_Value: accessed-variable=VeTINR_e_TCM_PassiveHybridGear.Value
            OUT_VeTINR_e_TargetGear_Value: accessed-variable=VeTINR_e_TargetGear.Value
            OUT_VeTINR_e_TCM_ClutchStartGear_Value: accessed-variable=VeTINR_e_TCM_ClutchStartGear.Value
            OUT_VeTINR_e_TransLimpRequest_Value: accessed-variable=VeTINR_e_TransLimpRequest.Value
            OUT_VeTINR_e_Synchro1Gear_Value: accessed-variable=VeTINR_e_Synchro1Gear.Value
            OUT_VeTINR_e_Synchro2Gear_Value: accessed-variable=VeTINR_e_Synchro2Gear.Value
            OUT_VeTINR_e_Synchro1Sts_Value: accessed-variable=VeTINR_e_Synchro1Sts.Value
            OUT_VeTINR_e_TCMTCCPreventionID_Value: accessed-variable=VeTINR_e_TCMTCCPreventionID.Value
            OUT_VaTINR_M_ClchTrq_Value: accessed-variable=VaTINR_M_ClchTrq.Value
            OUT_VeTINR_e_Clch1Sts_Value: accessed-variable=VeTINR_e_Clch1Sts.Value
            OUT_VeTINR_e_Clch3Sts_Value: accessed-variable=VeTINR_e_Clch3Sts.Value
            OUT_VeTINR_e_MtrBDynFctr_Value: accessed-variable=VeTINR_e_MtrBDynFctr.Value
      runnable TINR_PwrOn
        data-send-points:
          90 x access:
            OUT_VeTINR_e_TCMActMode_Value: accessed-variable=VeTINR_e_TCMActMode.Value
            OUT_VeTINR_b_Inhibit_Mode1_Value: accessed-variable=VeTINR_b_Inhibit_Mode1.Value
            OUT_VeTINR_e_Synchro2Gear_Value: accessed-variable=VeTINR_e_Synchro2Gear.Value
            OUT_VeTINR_b_Synchro2GearFA_Value: accessed-variable=VeTINR_b_Synchro2GearFA.Value
            OUT_VeTINR_Pct_TransStrssFctr_Value: accessed-variable=VeTINR_Pct_TransStrssFctr.Value
            OUT_VeTINR_b_DrvLnTrqRq_Axle_FA_Value: accessed-variable=VeTINR_b_DrvLnTrqRq_Axle_FA.Value
            OUT_VeTINR_e_Synchro1Sts_Value: accessed-variable=VeTINR_e_Synchro1Sts.Value
            OUT_VeTINR_e_ILEStat_Value: accessed-variable=VeTINR_e_ILEStat.Value
            OUT_VeTINR_b_ActualGearFA_Value: accessed-variable=VeTINR_b_ActualGearFA.Value
            OUT_VeTINR_b_DsblAEMD4TCM_Value: accessed-variable=VeTINR_b_DsblAEMD4TCM.Value
            OUT_VeTINR_b_TCMTrqCntrlMdSlwFA_Value: accessed-variable=VeTINR_b_TCMTrqCntrlMdSlwFA.Value
            OUT_VeTINR_b_TCMTrqCntrlMdFstFA_Value: accessed-variable=VeTINR_b_TCMTrqCntrlMdFstFA.Value
            OUT_VeTINR_b_Inhibit_Mode2_Value: accessed-variable=VeTINR_b_Inhibit_Mode2.Value
            OUT_VeTINR_b_Inhibit_Gear1_Value: accessed-variable=VeTINR_b_Inhibit_Gear1.Value
            OUT_VeTINR_b_Inhibit_Gear2_Value: accessed-variable=VeTINR_b_Inhibit_Gear2.Value
            OUT_VeTINR_e_TargetGear_Value: accessed-variable=VeTINR_e_TargetGear.Value
            OUT_VeTINR_b_Inhibit_Gear3_Value: accessed-variable=VeTINR_b_Inhibit_Gear3.Value
            OUT_VeTINR_b_Inhibit_Gear4_Value: accessed-variable=VeTINR_b_Inhibit_Gear4.Value
            OUT_VeTINR_b_Inhibit_Neutral_Value: accessed-variable=VeTINR_b_Inhibit_Neutral.Value
            OUT_VeTINR_e_HASStatusK0_Value: accessed-variable=VeTINR_e_HASStatusK0.Value
            OUT_VeTINR_b_KGB_Value: accessed-variable=VeTINR_b_KGB.Value
            OUT_VeTINR_b_KOB_Value: accessed-variable=VeTINR_b_KOB.Value
            OUT_VeTINR_b_KSB_Value: accessed-variable=VeTINR_b_KSB.Value
            OUT_VeTINR_e_ActualGear_Value: accessed-variable=VeTINR_e_ActualGear.Value
            OUT_VeTINR_i_TCM_DriveProgram_Value: accessed-variable=VeTINR_i_TCM_DriveProgram.Value
            OUT_VeTINR_Cnt_TCM_DriverType_Value: accessed-variable=VeTINR_Cnt_TCM_DriverType.Value
            OUT_VeTINR_e_TCMTrqCntrlMdSlw_Value: accessed-variable=VeTINR_e_TCMTrqCntrlMdSlw.Value
            OUT_VeTINR_b_TCMActModeFA_Value: accessed-variable=VeTINR_b_TCMActModeFA.Value
            OUT_VeTINR_e_ShftType_Value: accessed-variable=VeTINR_e_ShftType.Value
            OUT_VeTINR_b_ShftTypeFA_Value: accessed-variable=VeTINR_b_ShftTypeFA.Value
            OUT_VeTINR_e_TCMStrtStpOvrrd_Value: accessed-variable=VeTINR_e_TCMStrtStpOvrrd.Value
            OUT_VeTINR_e_TCMTrqCntrlMdFst_Value: accessed-variable=VeTINR_e_TCMTrqCntrlMdFst.Value
            OUT_VeTINR_b_TCMTransReqFuelON_Value: accessed-variable=VeTINR_b_TCMTransReqFuelON.Value
            OUT_VeTINR_b_TCMSpdCtrlCapable_Value: accessed-variable=VeTINR_b_TCMSpdCtrlCapable.Value
            OUT_VeTINR_e_ComFailTCM_C1CAN_Value: accessed-variable=VeTINR_e_ComFailTCM_C1CAN.Value
            OUT_VeTINR_e_K1Status_Value: accessed-variable=VeTINR_e_K1Status.Value
            OUT_VeTINR_b_ILE_STO_Stat_Value: accessed-variable=VeTINR_b_ILE_STO_Stat.Value
            OUT_VeTINR_e_TCMModeReq_Value: accessed-variable=VeTINR_e_TCMModeReq.Value
            OUT_VeTINR_e_ComFailTCM_ePtCAN_Value: accessed-variable=VeTINR_e_ComFailTCM_ePtCAN.Value
            OUT_VeTINR_n_DisengageILE_Value: accessed-variable=VeTINR_n_DisengageILE.Value
            OUT_VeTINR_b_TargetGearFA_Value: accessed-variable=VeTINR_b_TargetGearFA.Value
            OUT_VeTINR_e_ShftTypeTLF_Value: accessed-variable=VeTINR_e_ShftTypeTLF.Value
            OUT_VeTINR_b_ShftTypeTLFFA_Value: accessed-variable=VeTINR_b_ShftTypeTLFFA.Value
            OUT_VeTINR_e_Synchro2Sts_Value: accessed-variable=VeTINR_e_Synchro2Sts.Value
            OUT_VeTINR_b_TCMTransTrqRatioFA_Value: accessed-variable=VeTINR_b_TCMTransTrqRatioFA.Value
            OUT_VeTINR_e_P2SpdCntrlReq_Value: accessed-variable=VeTINR_e_P2SpdCntrlReq.Value
            OUT_VeTINR_M_DrvLnTrqRq_Axle_Value: accessed-variable=VeTINR_M_DrvLnTrqRq_Axle.Value
            OUT_VeTINR_e_TCM_ClutchStartGear_Value: accessed-variable=VeTINR_e_TCM_ClutchStartGear.Value
            OUT_VeTINR_b_TCM_ASCReq_Value: accessed-variable=VeTINR_b_TCM_ASCReq.Value
            OUT_VeTINR_e_TCM_ActiveEVGear_Value: accessed-variable=VeTINR_e_TCM_ActiveEVGear.Value
            OUT_VeTINR_b_TCM_ActiveEVGearFA_Value: accessed-variable=VeTINR_b_TCM_ActiveEVGearFA.Value
            OUT_VeTINR_e_TCM_ActiveXNGear_Value: accessed-variable=VeTINR_e_TCM_ActiveXNGear.Value
            OUT_VeTINR_b_TCM_ActiveXNGearFA_Value: accessed-variable=VeTINR_b_TCM_ActiveXNGearFA.Value
            OUT_VeTINR_e_TCM_ActiveHybridGear_Value: accessed-variable=VeTINR_e_TCM_ActiveHybridGear.Value
            OUT_VeTINR_b_TCM_ActiveHybridGearFA_Value: accessed-variable=VeTINR_b_TCM_ActiveHybridGearFA.Value
            OUT_VeTINR_e_TCM_PassiveHybridGear_Value: accessed-variable=VeTINR_e_TCM_PassiveHybridGear.Value
            OUT_VeTINR_b_TCM_PassiveHybridGearFA_Value: accessed-variable=VeTINR_b_TCM_PassiveHybridGearFA.Value
            OUT_VeTINR_d_EngStrtTypAvbl_Value: accessed-variable=VeTINR_d_EngStrtTypAvbl.Value
            OUT_VeTINR_b_EngStrtTypAvblFA_Value: accessed-variable=VeTINR_b_EngStrtTypAvblFA.Value
            OUT_VeTINR_e_Synchro1Gear_Value: accessed-variable=VeTINR_e_Synchro1Gear.Value
            OUT_VeTINR_b_Synchro1GearFA_Value: accessed-variable=VeTINR_b_Synchro1GearFA.Value
            OUT_VeTINR_r_TCMTransTrqRatio_Value: accessed-variable=VeTINR_r_TCMTransTrqRatio.Value
            OUT_VeTINR_r_TCM_HillMode_Value: accessed-variable=VeTINR_r_TCM_HillMode.Value
            OUT_VeTINR_b_PwrFlowStatus_Value: accessed-variable=VeTINR_b_PwrFlowStatus.Value
            OUT_VeTINR_d_TCMLimphomeFaults_Value: accessed-variable=VeTINR_d_TCMLimphomeFaults.Value
            OUT_VeTINR_b_TCMLimphomeFaultsFA_Value: accessed-variable=VeTINR_b_TCMLimphomeFaultsFA.Value
            OUT_VeTINR_i_MinGearAllwd_Value: accessed-variable=VeTINR_i_MinGearAllwd.Value
            OUT_VeTINR_i_MaxGearAllwd_Value: accessed-variable=VeTINR_i_MaxGearAllwd.Value
            OUT_VaTINR_n_NiMinForLockUp_Value: accessed-variable=VaTINR_n_NiMinForLockUp.Value
            OUT_VaTINR_n_NiMinToOpen_Value: accessed-variable=VaTINR_n_NiMinToOpen.Value
            OUT_VaTINR_n_NiMinToOpenCoast_Value: accessed-variable=VaTINR_n_NiMinToOpenCoast.Value
            OUT_VaTINR_n_NiMinForLockUpCoast_Value: accessed-variable=VaTINR_n_NiMinForLockUpCoast.Value
            OUT_VeTINR_e_TransAdpSts_Value: accessed-variable=VeTINR_e_TransAdpSts.Value
            OUT_VeTINR_d_TCMFailures_Value: accessed-variable=VeTINR_d_TCMFailures.Value
            OUT_VeTINR_e_TCMTCCPreventionID_Value: accessed-variable=VeTINR_e_TCMTCCPreventionID.Value
            OUT_VaTINR_M_ClchTrq_Value: accessed-variable=VaTINR_M_ClchTrq.Value
            OUT_VeTINR_b_ClchTrqFA_Value: accessed-variable=VeTINR_b_ClchTrqFA.Value
            OUT_VeTINR_M_ActualClch1_TCM_Value: accessed-variable=VeTINR_M_ActualClch1_TCM.Value
            OUT_VeTINR_M_ActualClch3_TCM_Value: accessed-variable=VeTINR_M_ActualClch3_TCM.Value
            OUT_VeTINR_e_Clch1Sts_Value: accessed-variable=VeTINR_e_Clch1Sts.Value
            OUT_VeTINR_e_Clch3Sts_Value: accessed-variable=VeTINR_e_Clch3Sts.Value
            OUT_VeTINR_e_MtrBDynFctr_Value: accessed-variable=VeTINR_e_MtrBDynFctr.Value
            OUT_VeTINR_b_ClchFaultActv_Value: accessed-variable=VeTINR_b_ClchFaultActv.Value
            OUT_VeTINR_t_TCM_TimeToSpeedChange_Value: accessed-variable=VeTINR_t_TCM_TimeToSpeedChange.Value
            OUT_VeTINR_e_TransLimpRequest_Value: accessed-variable=VeTINR_e_TransLimpRequest.Value
            OUT_VeTINR_b_DrvLnMinTrqMd_Value: accessed-variable=VeTINR_b_DrvLnMinTrqMd.Value
            OUT_VeTINR_r_Mech_DrivelineRatio_Value: accessed-variable=VeTINR_r_Mech_DrivelineRatio.Value
            OUT_VeTINR_b_Mech_DrivelineRatioFA_Value: accessed-variable=VeTINR_b_Mech_DrivelineRatioFA.Value
            OUT_VeTINR_r_TCC_TR_Gen4_Value: accessed-variable=VeTINR_r_TCC_TR_Gen4.Value
            OUT_VeTINR_b_TCC_TR_Gen4FA_Value: accessed-variable=VeTINR_b_TCC_TR_Gen4FA.Value
        written-local-variables:
          59 x access:
            WV_VeTINR_b_ActualClutch1_TCMFA_write_IRV: accessed-variable=VeTINR_b_ActualClutch1_TCMFA_write_IRV
            WV_VeTINR_b_ActualClutch3_TCMFA_write_IRV: accessed-variable=VeTINR_b_ActualClutch3_TCMFA_write_IRV
            WV_VeTINR_M_ActualClutch1_TCM_write_IRV: accessed-variable=VeTINR_M_ActualClutch1_TCM_write_IRV
            WV_VeTINR_M_ActualClutch3_TCM_write_IRV: accessed-variable=VeTINR_M_ActualClutch3_TCM_write_IRV
            WV_VeTINR_b_Clch1StsFA_write_IRV: accessed-variable=VeTINR_b_Clch1StsFA_write_IRV
            WV_VeTINR_e_Clch1Sts_write_IRV: accessed-variable=VeTINR_e_Clch1Sts_write_IRV
            WV_VeTINR_b_Clch3StsFA_write_IRV: accessed-variable=VeTINR_b_Clch3StsFA_write_IRV
            WV_VeTINR_e_Clch3Sts_write_IRV: accessed-variable=VeTINR_e_Clch3Sts_write_IRV
            WV_VeTINR_b_ClchTrqAFA_write_IRV: accessed-variable=VeTINR_b_ClchTrqAFA_write_IRV
            WV_VeTINR_M_ClchTrqA_write_IRV: accessed-variable=VeTINR_M_ClchTrqA_write_IRV
            WV_VeTINR_b_ClchTrqBFA_write_IRV: accessed-variable=VeTINR_b_ClchTrqBFA_write_IRV
            WV_VeTINR_M_ClchTrqB_write_IRV: accessed-variable=VeTINR_M_ClchTrqB_write_IRV
            WV_VeTINR_b_ClchTrqCFA_write_IRV: accessed-variable=VeTINR_b_ClchTrqCFA_write_IRV
            WV_VeTINR_M_ClchTrqC_write_IRV: accessed-variable=VeTINR_M_ClchTrqC_write_IRV
            WV_VeTINR_b_ClchTrqDFA_write_IRV: accessed-variable=VeTINR_b_ClchTrqDFA_write_IRV
            WV_VeTINR_M_ClchTrqD_write_IRV: accessed-variable=VeTINR_M_ClchTrqD_write_IRV
            WV_VeTINR_b_ClchTrqEFA_write_IRV: accessed-variable=VeTINR_b_ClchTrqEFA_write_IRV
            WV_VeTINR_M_ClchTrqE_write_IRV: accessed-variable=VeTINR_M_ClchTrqE_write_IRV
            WV_VeTINR_b_ClchTrqFFA_write_IRV: accessed-variable=VeTINR_b_ClchTrqFFA_write_IRV
            WV_VeTINR_M_ClchTrqF_write_IRV: accessed-variable=VeTINR_M_ClchTrqF_write_IRV
            WV_VeTINR_b_DriveLineRatioCanCFA_write_IRV: accessed-variable=VeTINR_b_DriveLineRatioCanCFA_write_IRV
            WV_VeTINR_b_DriveLineRatioEptFA_write_IRV: accessed-variable=VeTINR_b_DriveLineRatioEptFA_write_IRV
            WV_VeTINR_b_NiMinForLockUpCoastFA_write_IRV: accessed-variable=VeTINR_b_NiMinForLockUpCoastFA_write_IRV
            WV_VeTINR_b_NiMinForLockUpFA_write_IRV: accessed-variable=VeTINR_b_NiMinForLockUpFA_write_IRV
            WV_VeTINR_b_NiMinToOpenCoastFA_write_IRV: accessed-variable=VeTINR_b_NiMinToOpenCoastFA_write_IRV
            WV_VeTINR_b_NiMinToOpenFA_write_IRV: accessed-variable=VeTINR_b_NiMinToOpenFA_write_IRV
            WV_VeTINR_b_PwrFlowStatus_write_IRV: accessed-variable=VeTINR_b_PwrFlowStatus_write_IRV
            WV_VeTINR_b_TCMLimphomeFaultsC1CANFA_write_IRV: accessed-variable=VeTINR_b_TCMLimphomeFaultsC1CANFA_write_IRV
            WV_VeTINR_b_TCMLimphomeFaultsFA_write_IRV: accessed-variable=VeTINR_b_TCMLimphomeFaultsFA_write_IRV
            WV_VeTINR_b_TCMNeutPhsZeroTrqReq_CANCFA_write_IRV: accessed-variable=VeTINR_b_TCMNeutPhsZeroTrqReq_CANCFA_write_IRV
            WV_VeTINR_b_TCMNeutPhsZeroTrqReq_ePTCANFA_write_IRV: accessed-variable=VeTINR_b_TCMNeutPhsZeroTrqReq_ePTCANFA_write_IRV
            WV_VeTINR_b_TCM_MaxGearAllwdFA_write_IRV: accessed-variable=VeTINR_b_TCM_MaxGearAllwdFA_write_IRV
            WV_VeTINR_b_TCM_MinGearAllwdFA_write_IRV: accessed-variable=VeTINR_b_TCM_MinGearAllwdFA_write_IRV
            WV_VeTINR_d_TCMFailures_write_IRV: accessed-variable=VeTINR_d_TCMFailures_write_IRV
            WV_VeTINR_d_TCMLimphomeFaultsC1CAN_write_IRV: accessed-variable=VeTINR_d_TCMLimphomeFaultsC1CAN_write_IRV
            WV_VeTINR_d_TCMLimphomeFaults_write_IRV: accessed-variable=VeTINR_d_TCMLimphomeFaults_write_IRV
            WV_VeTINR_e_TCMNeutPhsZeroTrqReq_CANC_write_IRV: accessed-variable=VeTINR_e_TCMNeutPhsZeroTrqReq_CANC_write_IRV
            WV_VeTINR_e_TCMNeutPhsZeroTrqReq_ePTCAN_write_IRV: accessed-variable=VeTINR_e_TCMNeutPhsZeroTrqReq_ePTCAN_write_IRV
            WV_VeTINR_e_TransAdpStatus_write_IRV: accessed-variable=VeTINR_e_TransAdpStatus_write_IRV
            WV_VeTINR_i_TCM_MaxGearAllwd_write_IRV: accessed-variable=VeTINR_i_TCM_MaxGearAllwd_write_IRV
            WV_VeTINR_i_TCM_MinGearAllwd_write_IRV: accessed-variable=VeTINR_i_TCM_MinGearAllwd_write_IRV
            WV_VaTINR_n_NiMinForLockUpCoast_write_IRV: accessed-variable=VaTINR_n_NiMinForLockUpCoast_write_IRV
            WV_VaTINR_n_NiMinForLockUp_write_IRV: accessed-variable=VaTINR_n_NiMinForLockUp_write_IRV
            WV_VaTINR_n_NiMinToOpenCoast_write_IRV: accessed-variable=VaTINR_n_NiMinToOpenCoast_write_IRV
            WV_VaTINR_n_NiMinToOpen_write_IRV: accessed-variable=VaTINR_n_NiMinToOpen_write_IRV
            WV_VeTINR_r_DriveLineRatioCanC_write_IRV: accessed-variable=VeTINR_r_DriveLineRatioCanC_write_IRV
            WV_VeTINR_r_DriveLineRatioEpt_write_IRV: accessed-variable=VeTINR_r_DriveLineRatioEpt_write_IRV
            WV_VeTINR_r_TCM_HillMode_write_IRV: accessed-variable=VeTINR_r_TCM_HillMode_write_IRV
            WV_VeTINR_r_TransTrqRatio_write_IRV: accessed-variable=VeTINR_r_TransTrqRatio_write_IRV
            WV_VeTINR_b_LeadClutch1_TCMFA_write_IRV: accessed-variable=VeTINR_b_LeadClutch1_TCMFA_write_IRV
            WV_VeTINR_M_LeadClutch1_TCM_write_IRV: accessed-variable=VeTINR_M_LeadClutch1_TCM_write_IRV
            WV_VeTINR_b_LeadClutch3_TCMFA_write_IRV: accessed-variable=VeTINR_b_LeadClutch3_TCMFA_write_IRV
            WV_VeTINR_M_LeadClutch3_TCM_write_IRV: accessed-variable=VeTINR_M_LeadClutch3_TCM_write_IRV
            WV_VeTINR_b_DrvLnTrqRq_Axle_write_IRV: accessed-variable=VeTINR_b_DrvLnTrqRq_Axle_write_IRV
            WV_VeTINR_e_MtrBDynFctr_write_IRV: accessed-variable=VeTINR_e_MtrBDynFctr_write_IRV
            WV_VeTINR_e_TCMTCCPreventionID_write_IRV: accessed-variable=VeTINR_e_TCMTCCPreventionID_write_IRV
            WV_VeTINR_b_DrvLnMinTrqMd_write_IRV: accessed-variable=VeTINR_b_DrvLnMinTrqMd_write_IRV
            WV_VeTINR_b_DrvLnTrqRq_AxleFA_write_IRV: accessed-variable=VeTINR_b_DrvLnTrqRq_AxleFA_write_IRV
            WV_VeTINR_t_TCM_TimeToSpeedChange_write_IRV: accessed-variable=VeTINR_t_TCM_TimeToSpeedChange_write_IRV
      variation point proxy Variant_TINR_1: category=CONDITION, condition-access=0
